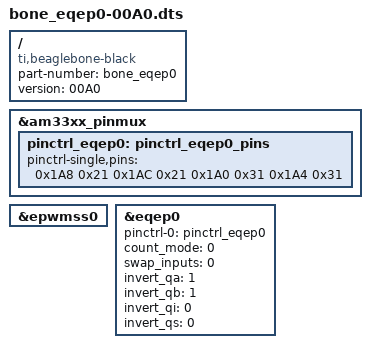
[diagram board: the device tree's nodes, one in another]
/*
 * Copyright (C) 2013 Nathaniel R. Lewis - http://teknoman117.wordpress.com/
 *
 * This program is free software; you can redistribute it and/or modify
 * it under the terms of the GNU General Public License version 2 as
 * published by the Free Software Foundation.
 *
 * Enable eQEP0 on the Beaglebone Black - incompatible with BB White because
 * most of the eQEP0 pins on Beaglebone white are not broken out.
 */
/dts-v1/;
/plugin/;

/ {
	compatible = "ti,beaglebone-black", "ti,beaglebone-green";

    /* identification */
    part-number = "bone_eqep0";
    version     = "00A0";

    fragment@0 {
        target = <&am33xx_pinmux>;
        __overlay__ {
		pinctrl_eqep0: pinctrl_eqep0_pins {
			pinctrl-single,pins = <
                        0x1A8 0x21  /* P9_41 = GPIO3_20 = EQEP0_index, MODE1 */
                        0x1AC 0x21  /* P9_25 = GPIO3_21 = EQEP0_strobe, MODE1 */
                        0x1A0 0x31  /* P9_42 = GPIO3_18 = EQEP0A_in, MODE1 */
                        0x1A4 0x31  /* P9_27 = GPIO3_19 = EQEP0B_in, MODE1 */
			>;
		};
        };
    };

    fragment@1 {
	target = <&epwmss0>;
	__overlay__ {
		status = "okay";
	};
    };

    fragment@2 {
	target = <&eqep0>;
	__overlay__ {
            pinctrl-names = "default";
            pinctrl-0 = <&pinctrl_eqep0>;

            count_mode = <0>;  /* 0 - Quadrature mode, normal 90 phase offset cha & chb.  1 - Direction mode.  cha input = clock, chb input = direction */
            swap_inputs = <0>; /* Are channel A and channel B swapped? (0 - no, 1 - yes) */
            invert_qa = <1>;   /* Should we invert the channel A input?  */
            invert_qb = <1>;   /* Should we invert the channel B input? I invert these because my encoder outputs drive transistors that pull down the pins */
            invert_qi = <0>;   /* Should we invert the index input? */
            invert_qs = <0>;   /* Should we invert the strobe input? */

	        status = "okay";
	};
    };
};
